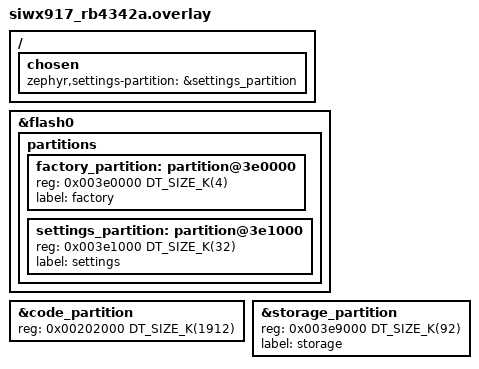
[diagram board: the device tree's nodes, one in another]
/*
 * Copyright (c) 2025 Project CHIP Authors
 *
 * Licensed under the Apache License, Version 2.0 (the "License");
 * you may not use this file except in compliance with the License.
 * You may obtain a copy of the License at
 *
 *     http://www.apache.org/licenses/LICENSE-2.0
 *
 * Unless required by applicable law or agreed to in writing, software
 * distributed under the License is distributed on an "AS IS" BASIS
 * WITHOUT WARRANTIES OR CONDITIONS OF ANY KIND, either express or implied.
 * See the License for the specific language governing permissions and
 * limitations under the License.
 */

/*
 * M4 free space ends at 0x400000 (start of SoC ota_swap_partition).
 * code (1912) + factory (4) + settings (32) + storage (92) = 2040 KiB.
 * Do not place app NVM inside ota_swap — that region is owned by the
 * NWP/Security Bootloader for RPS firmware upgrade.
 *
 * Zephyr factory-data contract (shared with matter_provisioning GFW via
 * provision.py --rtos zephyr Init flash_addr/flash_size):
 *   settings_partition @ 0x003e1000, size 0x8000 (32 KiB)
 * Matter KVS + provisioned factory keys (mt-fct/, mt-sl-fct/) live here.
 * factory_partition is reserved (unused by ProvisionStorageZephyr).
 */
/ {
	chosen {
		zephyr,settings-partition = &settings_partition;
	};
};

&flash0 {
	partitions {
		factory_partition: partition@3e0000 {
			reg = <0x003e0000 DT_SIZE_K(4)>;
			label = "factory";
		};

		settings_partition: partition@3e1000 {
			reg = <0x003e1000 DT_SIZE_K(32)>;
			label = "settings";
		};
	};
};

&code_partition {
	reg = <0x00202000 DT_SIZE_K(1912)>;
};

&storage_partition {
	reg = <0x003e9000 DT_SIZE_K(92)>;
	label = "storage";
};
